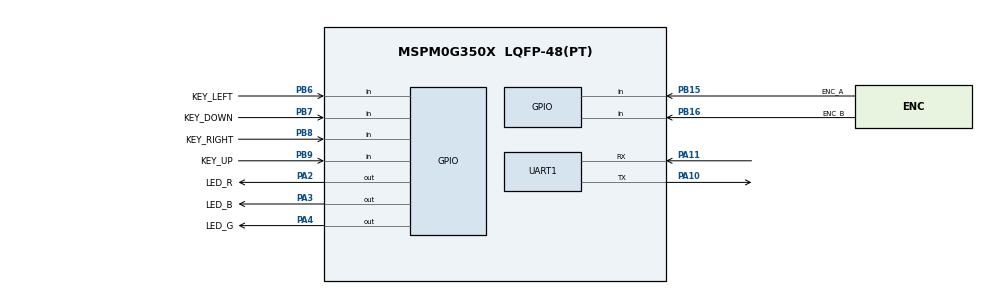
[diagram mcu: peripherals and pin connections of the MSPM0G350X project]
/**
 * @cliArgs --device "MSPM0G350X" --part "Default" --package "LQFP-48(PT)" --product "mspm0_sdk@2.10.00.04"
 * @versions {"tool":"1.27.0+4565"}
 */

/**
 * Import the modules used in this configuration.
 */
const GPIO   = scripting.addModule("/ti/driverlib/GPIO", {}, false);
const GPIO1  = GPIO.addInstance();
const GPIO2  = GPIO.addInstance();
const SYSCTL = scripting.addModule("/ti/driverlib/SYSCTL");
const UART   = scripting.addModule("/ti/driverlib/UART", {}, false);
const UART1  = UART.addInstance();

/**
 * Write custom configuration values to the imported modules.
 */
GPIO1.$name                         = "GPIO_MAIN";
GPIO1.port                          = "PORTA";
GPIO1.associatedPins.create(3);
GPIO1.associatedPins[0].$name       = "LED_R";
GPIO1.associatedPins[0].assignedPin = "2";
GPIO1.associatedPins[0].ioStructure = "SD";
GPIO1.associatedPins[0].pin.$assign = "PA2";
GPIO1.associatedPins[1].$name       = "LED_B";
GPIO1.associatedPins[1].assignedPin = "3";
GPIO1.associatedPins[1].ioStructure = "SD";
GPIO1.associatedPins[1].pin.$assign = "PA3";
GPIO1.associatedPins[2].$name       = "LED_G";
GPIO1.associatedPins[2].assignedPin = "4";
GPIO1.associatedPins[2].ioStructure = "SD";
GPIO1.associatedPins[2].pin.$assign = "PA4";

const Board = scripting.addModule("/ti/driverlib/Board", {}, false);

GPIO2.$name                              = "GPIO_PORTB_INPUTS";
GPIO2.port                               = "PORTB";
GPIO2.associatedPins.create(7);
GPIO2.associatedPins[0].$name            = "KEY_LEFT";
GPIO2.associatedPins[0].assignedPin      = "6";
GPIO2.associatedPins[0].direction        = "INPUT";
GPIO2.associatedPins[0].ioStructure      = "SD";
GPIO2.associatedPins[0].internalResistor = "PULL_UP";
GPIO2.associatedPins[0].pin.$assign      = "PB6";
GPIO2.associatedPins[1].$name            = "KEY_RIGHT";
GPIO2.associatedPins[1].assignedPin      = "8";
GPIO2.associatedPins[1].direction        = "INPUT";
GPIO2.associatedPins[1].ioStructure      = "SD";
GPIO2.associatedPins[1].internalResistor = "PULL_UP";
GPIO2.associatedPins[1].pin.$assign      = "PB8";
GPIO2.associatedPins[2].$name            = "KEY_UP";
GPIO2.associatedPins[2].assignedPin      = "9";
GPIO2.associatedPins[2].direction        = "INPUT";
GPIO2.associatedPins[2].ioStructure      = "SD";
GPIO2.associatedPins[2].internalResistor = "PULL_UP";
GPIO2.associatedPins[2].pin.$assign      = "PB9";
GPIO2.associatedPins[3].$name            = "KEY_DOWN";
GPIO2.associatedPins[3].direction        = "INPUT";
GPIO2.associatedPins[3].ioStructure      = "SD";
GPIO2.associatedPins[3].assignedPin      = "7";
GPIO2.associatedPins[3].internalResistor = "PULL_UP";
GPIO2.associatedPins[3].pin.$assign      = "PB7";
GPIO2.associatedPins[4].$name            = "ENC_A";
GPIO2.associatedPins[4].assignedPin      = "15";
GPIO2.associatedPins[4].direction        = "INPUT";
GPIO2.associatedPins[4].ioStructure      = "SD";
GPIO2.associatedPins[4].pin.$assign      = "PB15";
GPIO2.associatedPins[5].$name            = "ENC_B";
GPIO2.associatedPins[5].assignedPin      = "16";
GPIO2.associatedPins[5].direction        = "INPUT";
GPIO2.associatedPins[5].ioStructure      = "SD";
GPIO2.associatedPins[5].pin.$assign      = "PB16";
GPIO2.associatedPins[6].$name            = "KEY_MID";
GPIO2.associatedPins[6].direction        = "INPUT";
GPIO2.associatedPins[6].ioStructure      = "SD";
GPIO2.associatedPins[6].assignedPin      = "14";
GPIO2.associatedPins[6].internalResistor = "PULL_UP";

SYSCTL.forceDefaultClkConfig = true;
SYSCTL.clockTreeEn           = true;

UART1.$name                            = "UART_DEBUG";
UART1.targetBaudRate                   = 115200;
UART1.enableFIFO                       = true;
UART1.rxFifoThreshold                  = "DL_UART_RX_FIFO_LEVEL_ONE_ENTRY";
UART1.enableDMARX                      = false;
UART1.enableDMATX                      = false;
UART1.enableInternalLoopback           = true;
UART1.peripheral.$assign               = "UART0";
UART1.peripheral.rxPin.$assign         = "PA11";
UART1.peripheral.txPin.$assign         = "PA10";
UART1.txPinConfig.$name                = "ti_driverlib_gpio_GPIOPinGeneric0";
UART1.txPinConfig.direction            = scripting.forceWrite("OUTPUT");
UART1.txPinConfig.hideOutputInversion  = scripting.forceWrite(false);
UART1.txPinConfig.onlyInternalResistor = scripting.forceWrite(false);
UART1.txPinConfig.passedPeripheralType = scripting.forceWrite("Digital");
UART1.rxPinConfig.$name                = "ti_driverlib_gpio_GPIOPinGeneric1";
UART1.rxPinConfig.hideOutputInversion  = scripting.forceWrite(false);
UART1.rxPinConfig.onlyInternalResistor = scripting.forceWrite(false);
UART1.rxPinConfig.passedPeripheralType = scripting.forceWrite("Digital");

const ProjectConfig              = scripting.addModule("/ti/project_config/ProjectConfig", {}, false);
ProjectConfig.migrationCondition = true;

/**
 * Pinmux solution for unlocked pins/peripherals. This ensures that minor changes to the automatic solver in a future
 * version of the tool will not impact the pinmux you originally saw.  These lines can be completely deleted in order to
 * re-solve from scratch.
 */
Board.peripheral.$suggestSolution            = "DEBUGSS";
Board.peripheral.swclkPin.$suggestSolution   = "PA20";
Board.peripheral.swdioPin.$suggestSolution   = "PA19";
GPIO2.associatedPins[6].pin.$suggestSolution = "PB14";
